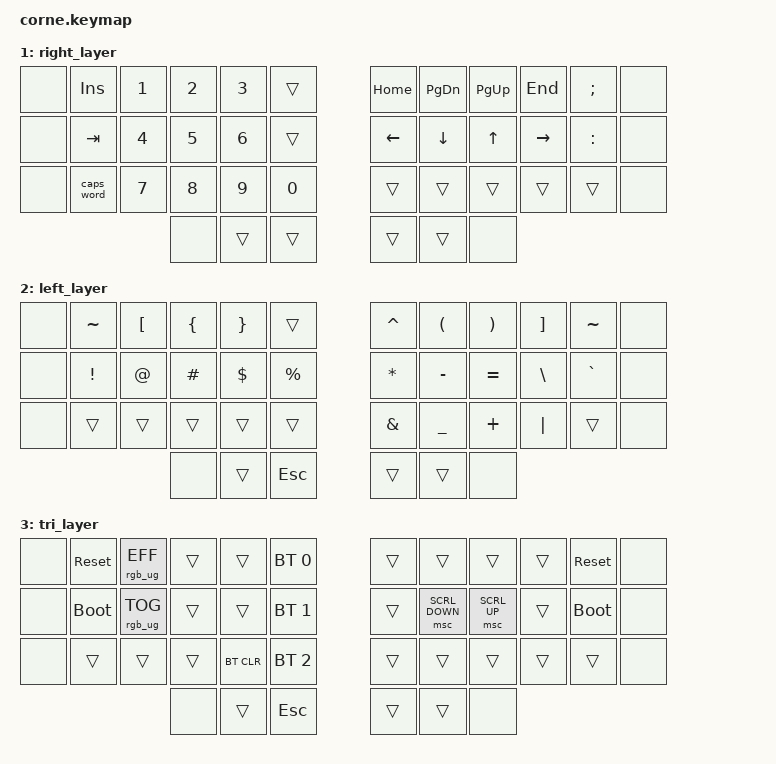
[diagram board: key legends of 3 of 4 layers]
/*
 * Copyright (c) 2020 The ZMK Contributors
 *
 * SPDX-License-Identifier: MIT
 */

#include <behaviors.dtsi>
#include <dt-bindings/zmk/keys.h>
#include <dt-bindings/zmk/bt.h>
#include <dt-bindings/zmk/rgb.h>
#include "zmk-helpers/helper.h"
#include "zmk-helpers/key-labels/42.h"

#define ZMK_POINTING_DEFAULT_SCRL_VAL 15
#include <dt-bindings/zmk/pointing.h>

#define THUMBS_L LH0 LH1 
#define THUMBS_R RH0 RH1
#define KEYS_L LT0 LT1 LT2 LT3 LT4\
  LM0 LM1 LM2 LM3 LM4\
  LB0 LB1 LB2 LB3 LB4
#define KEYS_R RT0 RT1 RT2 RT3 RT4\
  RM0 RM1 RM2 RM3 RM4\
  RB0 RB1 RB2 RB3 RB4

// Home row mods macro
#define HRML(k1,k2,k3,k4) &hmls LSHFT k1  &hml LCTRL k2  &hml LALT k3  &hml LGUI k4
#define HRMR(k1,k2,k3,k4) &hmr RGUI k1  &hmr RALT k2  &hmr RCTRL k3  &hmrs RSHFT k4

&lt {
  flavor = "balanced"; 
  tapping-term-ms = <220>;
  quick-tap-ms = <170>;
  retro-tap;
};

/ {
    behaviors {
        hmls: home_row_mod_left_shift {
            compatible = "zmk,behavior-hold-tap";
            #binding-cells = <2>;
            flavor = "balanced";
            tapping-term-ms = <200>;
            quick-tap-ms = <170>;
            require-prior-idle-ms = <100>;
            bindings = <&kp>, <&kp>;
            hold-trigger-key-positions = <KEYS_R THUMBS_R THUMBS_L>;
            hold-trigger-on-release;
        };
        hmrs: home_row_mod_right_shift {
            compatible = "zmk,behavior-hold-tap";
            #binding-cells = <2>;
            flavor = "balanced";
            tapping-term-ms = <200>;
            quick-tap-ms = <170>;
            bindings = <&kp>, <&kp>;
            require-prior-idle-ms = <100>;
            hold-trigger-key-positions = <KEYS_L THUMBS_R THUMBS_L>;
            hold-trigger-on-release;
        };
        hml: home_row_mod_left {
            compatible = "zmk,behavior-hold-tap";
            #binding-cells = <2>;
            flavor = "balanced";
            tapping-term-ms = <220>;
            quick-tap-ms = <170>;
            require-prior-idle-ms = <130>;
            bindings = <&kp>, <&kp>;
            hold-trigger-key-positions = <KEYS_R THUMBS_R THUMBS_L>;
            hold-trigger-on-release;
        };
        hmr: home_row_mod_right {
            compatible = "zmk,behavior-hold-tap";
            #binding-cells = <2>;
            flavor = "balanced";
            tapping-term-ms = <220>;
            quick-tap-ms = <170>;
            bindings = <&kp>, <&kp>;
            require-prior-idle-ms = <130>;
            hold-trigger-key-positions = <KEYS_L THUMBS_R THUMBS_L>;
            hold-trigger-on-release;
        };
    };
    conditional_layers {
        compatible = "zmk,conditional-layers";
        tri_layer {
            if-layers = <1 2>;
            then-layer = <3>;
        };
    };

    keymap {
        compatible = "zmk,keymap";
        default_layer {
            bindings = <
        //╭──────────┬──────────┬──────────┬──────────┬──────────┬──────────╮   ╭──────────┬──────────┬──────────┬──────────┬──────────┬─────────╮
        //│          │  Q       │  W       │  E       │  R       │  T       │   │  Y       │  U       │  I       │  O       │  P       │         │
            &none      &kp Q      &kp W      &kp E      &kp R      &kp T          &kp Y      &kp U      &kp I      &kp O      &kp P      &none
        //├──────────┼──────────┼──────────┼──────────┼──────────┼──────────┤   ├──────────┼──────────┼──────────┼──────────┼──────────┼─────────┤
        //│          │  A       │  S       │  D       │  F       │  G       │   │  H       │  J       │  K       │  L       │ ' "      │         │
            &none      HRML(A,        S,         D,         F)     &kp G          &kp H      HRMR(J,        K,         L,        SQT)    &none
        //├──────────┼──────────┼──────────┼──────────┼──────────┼──────────┤   ├──────────┼──────────┼──────────┼──────────┼──────────┼─────────┤
        //│          │  Z       │  X       │  C       │  V       │  B       │   │  N       │  M       │ , <      │ . >      │ / ?      │         │
            &none      &kp Z      &kp X      &kp C      &kp V      &kp B          &kp N      &kp M      &kp COMMA  &kp DOT    &kp FSLH   &none 
        //╰──────────┴──────────┴──────────┴──────────┼──────────┼──────────┤   ├──────────┼──────────┼──────────┴──────────┴──────────┴─────────╯
                                             &none      &lt 2 ESC  &kp BSPC      &kp SPACE  &lt 1 ENTER &none
        //                                  ╰─────────┴──────────┴──────────╯   ╰──────────┴───────────────────╯
            >;
        };
 
        right_layer {
            bindings = <
        //╭──────────┬──────────┬──────────┬──────────┬──────────┬──────────╮   ╭──────────┬──────────┬──────────┬──────────┬─────────┬─────────╮
        //│          │ INSERT   │  1       │  2       │  3       │          │   │ HOME     │ PAGE DN  │ PAGE UP  │ END      │  ;      │         │
            &none     &kp INS    &kp N1     &kp N2     &kp N3     &trans         &kp HOME   &kp PG_DN  &kp PG_UP  &kp END    &kp SEMI   &none
        //├──────────┼──────────┼──────────┼──────────┼──────────┼──────────┤   ├──────────┼──────────┼──────────┼──────────┼─────────┼─────────┤
        //│          │ DELETE   │  4       │  5       │  6       │          │   │ LEFT     │ DOWN     │ UP       │ RIGHT    │  :      │         │
            &none     &kp TAB    &kp N4     &kp N5     &kp N6     &trans         &kp LEFT   &kp DOWN   &kp UP     &kp RIGHT   &kp COLON  &none
        //├──────────┼──────────┼──────────┼──────────┼──────────┼──────────┤   ├──────────┼──────────┼──────────┼──────────┼─────────┼─────────┤
        //│          │ CAPS     │  7       │  8       │  9       │  0       │   │          │          │          │          │         │         │
            &none     &caps_word  &kp N7     &kp N8     &kp N9     &kp N0         &trans     &trans     &trans     &trans     &trans    &none 
        //╰──────────┴──────────┴──────────┴──────────┼──────────┼──────────┤   ├──────────┼──────────┼──────────┴──────────┴─────────┴─────────╯
                                             &none      &trans     &trans         &trans     &trans     &none
       //                                  ╰─────────┴──────────┴──────────╯   ╰──────────┴───────────────────╯
            >;
       };

        left_layer {
            bindings = <
        //╭──────────┬──────────┬──────────┬──────────┬──────────┬──────────╮   ╭──────────┬──────────┬──────────┬──────────┬──────────┬─────────╮
        //│          │          │  [       │  {       │  }       │          │   │  ^       │  (       │  )       │  ]       │  ~       │         │
            &none      &kp TILDE  &kp LBKT   &kp LBRC   &kp RBRC   &trans         &kp CARET  &kp LPAR   &kp RPAR   &kp RBKT   &kp TILDE  &none
        //├──────────┼──────────┼──────────┼──────────┼──────────┼──────────┤   ├──────────┼──────────┼──────────┼──────────┼──────────┼─────────┤
        //│          │  !       │  @       │  #       │  $       │  %       │   │  *       │  -       │  =       │  \       │  `       │         │
            &none      &kp EXCL   &kp AT     &kp HASH   &kp DLLR   &kp PRCNT      &kp ASTRK  &kp MINUS  &kp EQUAL  &kp BSLH   &kp GRAVE  &none
        //├──────────┼──────────┼──────────┼──────────┼──────────┼──────────┤   ├──────────┼──────────┼──────────┼──────────┼──────────┼─────────┤
        //│          │          │          │          │          │          │   │  &       │  _       │  +       │  │       │          │         │
            &none      &trans     &trans     &trans     &trans     &trans         &kp AMPS   &kp UNDER  &kp PLUS   &kp PIPE   &trans     &none 
        //╰──────────┴──────────┴──────────┴──────────┼──────────┼──────────┤   ├──────────┼──────────┼──────────┴──────────┴──────────┴─────────╯
                                             &none      &trans     &kp ESC        &trans     &trans     &none
        //                                  ╰─────────┴──────────┴──────────╯   ╰──────────┴───────────────────╯
            >;
        };

        tri_layer {
            bindings = <
        //╭──────────┬──────────┬──────────┬──────────┬──────────┬──────────╮   ╭──────────┬──────────┬──────────┬──────────┬──────────┬─────────╮
        //│          │ RESET    │          │          │          │PROFILE 0 │   │          │          │          │          │  RESET   │         │
            &none     &sys_reset  &rgb_ug RGB_EFF &trans &trans   &bt BT_SEL 0    &trans     &trans     &trans     &trans    &sys_reset  &none
        //├──────────┼──────────┼──────────┼──────────┼──────────┼──────────┤   ├──────────┼──────────┼──────────┼──────────┼──────────┼─────────┤
        //│          │BOOTLOADER│          │          │          │PROFILE 1 │   │          │          │          │          │BOOTLOADER│         │
            &none     &bootloader &rgb_ug RGB_TOG &trans &trans   &bt BT_SEL 1    &trans   &msc SCRL_DOWN &msc SCRL_UP &trans &bootloader &none
        //├──────────┼──────────┼──────────┼──────────┼──────────┼──────────┤   ├──────────┼──────────┼──────────┼──────────┼──────────┼─────────┤
        //│          │          │          │          │ CLEAR BT │PROFILE 2 │   │          │          │          │          │          │         │
            &none      &trans     &trans     &trans    &bt BT_CLR &bt BT_SEL 2    &trans     &trans     &trans     &trans     &trans     &none 
        //╰──────────┴──────────┴──────────┴──────────┼──────────┼──────────┤   ├──────────┼──────────┼──────────┴──────────┴──────────┴─────────╯
                                             &none      &trans     &kp ESC        &trans     &trans     &none
        //                                  ╰─────────┴──────────┴──────────╯   ╰──────────┴───────────────────╯
            >;
        };
    };
};
